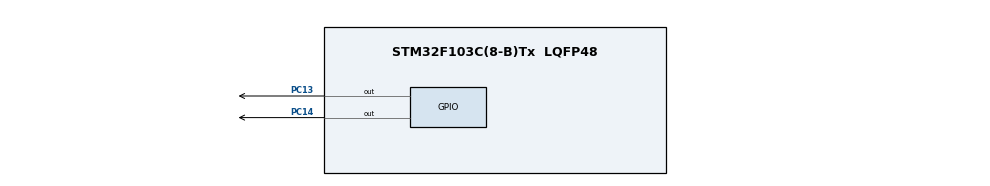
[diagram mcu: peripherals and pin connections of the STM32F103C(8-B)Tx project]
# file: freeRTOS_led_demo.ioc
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FREERTOS.Tasks01=LEDC13,24,128,StartLEDC13,Default,NULL,Dynamic,NULL,NULL;LEDC14,16,128,StartLEDC14,Default,NULL,Dynamic,NULL,NULL
FREERTOS.configUSE_NEWLIB_REENTRANT=1
Mcu.Family=STM32F1
Mcu.Name=STM32F103C(8-B)Tx
Mcu.Package=LQFP48
NVIC.PriorityGroup=NVIC_PRIORITYGROUP_4
NVIC.TIM4_IRQn=true\:15\:0\:false\:false\:true\:false\:false\:true\:true
NVIC.TimeBase=TIM4_IRQn
NVIC.TimeBaseIP=TIM4
PA13.Mode=Serial_Wire
PA13.Signal=SYS_JTMS-SWDIO
PA14.Mode=Serial_Wire
PA14.Signal=SYS_JTCK-SWCLK
PC13-TAMPER-RTC.Signal=GPIO_Output
PC14-OSC32_IN.Signal=GPIO_Output
ProjectManager.HeapSize=0x200
ProjectManager.StackSize=0x400
ProjectManager.TargetToolchain=STM32CubeIDE
RCC.APB1Freq_Value=8000000
RCC.APB2Freq_Value=8000000
VP_FREERTOS_VS_CMSIS_V2.Mode=CMSIS_V2
VP_SYS_VS_tim4.Mode=TIM4
board=custom

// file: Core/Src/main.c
/* USER CODE BEGIN Header */
/**
 ******************************************************************************
 * @file           : main.c
 * @brief          : Main program body
 ******************************************************************************
 * @attention
 *
 * Copyright (c) 2025 STMicroelectronics.
 * All rights reserved.
 *
 * This software is licensed under terms that can be found in the LICENSE file
 * in the root directory of this software component.
 * If no LICENSE file comes with this software, it is provided AS-IS.
 *
 ******************************************************************************
 */
/* USER CODE END Header */
#include "main.h"
#include "cmsis_os.h"

/* Definitions for LEDC13 */
osThreadId_t LEDC13Handle;
const osThreadAttr_t LEDC13_attributes = {
  .name = "LEDC13",
  .stack_size = 128 * 4,
  .priority = (osPriority_t) osPriorityNormal,
};
/* Definitions for LEDC14 */
osThreadId_t LEDC14Handle;
const osThreadAttr_t LEDC14_attributes = {
  .name = "LEDC14",
  .stack_size = 128 * 4,
  .priority = (osPriority_t) osPriorityBelowNormal,
};

void SystemClock_Config(void);
static void MX_GPIO_Init(void);
void StartLEDC13(void *argument);
void StartLEDC14(void *argument);

int main(void)
{

  /* MCU Configuration--------------------------------------------------------*/

  /* Reset of all peripherals, Initializes the Flash interface and the Systick. */
  HAL_Init();

  /* Configure the system clock */
  SystemClock_Config();

  /* Initialize all configured peripherals */
  MX_GPIO_Init();

  /* Init scheduler */
  osKernelInitialize();

  /* Create the thread(s) */
  /* creation of LEDC13 */
  LEDC13Handle = osThreadNew(StartLEDC13, NULL, &LEDC13_attributes);

  /* creation of LEDC14 */
  LEDC14Handle = osThreadNew(StartLEDC14, NULL, &LEDC14_attributes);

  /* Start scheduler */
  osKernelStart();

  /* We should never get here as control is now taken by the scheduler */

  /* Infinite loop */
	while (1) {

	}
}

void SystemClock_Config(void)
{
  RCC_OscInitTypeDef RCC_OscInitStruct = {0};
  RCC_ClkInitTypeDef RCC_ClkInitStruct = {0};

  /** Initializes the RCC Oscillators according to the specified parameters
  * in the RCC_OscInitTypeDef structure.
  */
  RCC_OscInitStruct.OscillatorType = RCC_OSCILLATORTYPE_HSI;
  RCC_OscInitStruct.HSIState = RCC_HSI_ON;
  RCC_OscInitStruct.HSICalibrationValue = RCC_HSICALIBRATION_DEFAULT;
  RCC_OscInitStruct.PLL.PLLState = RCC_PLL_NONE;
  if (HAL_RCC_OscConfig(&RCC_OscInitStruct) != HAL_OK)
  {
    Error_Handler();
  }

  /** Initializes the CPU, AHB and APB buses clocks
  */
  RCC_ClkInitStruct.ClockType = RCC_CLOCKTYPE_HCLK|RCC_CLOCKTYPE_SYSCLK
                              |RCC_CLOCKTYPE_PCLK1|RCC_CLOCKTYPE_PCLK2;
  RCC_ClkInitStruct.SYSCLKSource = RCC_SYSCLKSOURCE_HSI;
  RCC_ClkInitStruct.AHBCLKDivider = RCC_SYSCLK_DIV1;
  RCC_ClkInitStruct.APB1CLKDivider = RCC_HCLK_DIV1;
  RCC_ClkInitStruct.APB2CLKDivider = RCC_HCLK_DIV1;

  if (HAL_RCC_ClockConfig(&RCC_ClkInitStruct, FLASH_LATENCY_0) != HAL_OK)
  {
    Error_Handler();
  }
}

static void MX_GPIO_Init(void)
{
  GPIO_InitTypeDef GPIO_InitStruct = {0};

  /* GPIO Ports Clock Enable */
  __HAL_RCC_GPIOC_CLK_ENABLE();
  __HAL_RCC_GPIOA_CLK_ENABLE();

  /*Configure GPIO pin Output Level */
  HAL_GPIO_WritePin(GPIOC, GPIO_PIN_13|GPIO_PIN_14, GPIO_PIN_RESET);

  /*Configure GPIO pins : PC13 PC14 */
  GPIO_InitStruct.Pin = GPIO_PIN_13|GPIO_PIN_14;
  GPIO_InitStruct.Mode = GPIO_MODE_OUTPUT_PP;
  GPIO_InitStruct.Pull = GPIO_NOPULL;
  GPIO_InitStruct.Speed = GPIO_SPEED_FREQ_LOW;
  HAL_GPIO_Init(GPIOC, &GPIO_InitStruct);

}

void StartLEDC13(void *argument)
{
  /* USER CODE BEGIN 5 */
	/* Infinite loop */
	for (;;) {
		HAL_GPIO_TogglePin(GPIOC, GPIO_PIN_13);
		osDelay(200);
	}
  /* USER CODE END 5 */
}

void StartLEDC14(void *argument)
{
  /* USER CODE BEGIN StartLEDC14 */
	/* Infinite loop */
	for (;;) {
		HAL_GPIO_TogglePin(GPIOC, GPIO_PIN_14);
		osDelay(400);
	}
  /* USER CODE END StartLEDC14 */
}

void HAL_TIM_PeriodElapsedCallback(TIM_HandleTypeDef *htim)
{
  if (htim->Instance == TIM4)
  {
    HAL_IncTick();
  }
}

void Error_Handler(void)
{
	__disable_irq();
	while (1) {
	}
}
